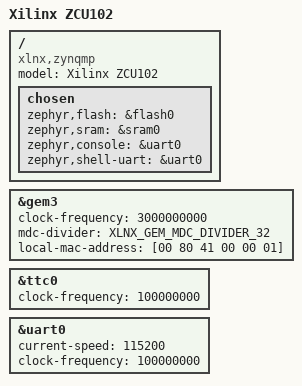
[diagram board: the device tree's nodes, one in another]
/*
 * Copyright (c) 2020, Weidmueller Interface GmbH & Co. KG
 * SPDX-License-Identifier: Apache-2.0
 */

/dts-v1/;

#include <arm/xilinx/zynqmp_rpu.dtsi>
#include <dt-bindings/ethernet/xlnx_gem.h>

/ {
	model = "Xilinx ZCU102";
	compatible = "xlnx,zynqmp";

	chosen {
		zephyr,flash      = &flash0;
		zephyr,sram       = &sram0;
		zephyr,console    = &uart0;
		zephyr,shell-uart = &uart0;
	};
};

&gem3 {
	status = "okay";
	clock-frequency = <3000000000>;
	mdc-divider = <XLNX_GEM_MDC_DIVIDER_32>;
	local-mac-address = [00 80 41 00 00 01];
};

&ttc0 {
	status = "okay";
	clock-frequency = <100000000>;
};

&uart0 {
	status = "okay";
	current-speed = <115200>;
	clock-frequency = <100000000>;
};
